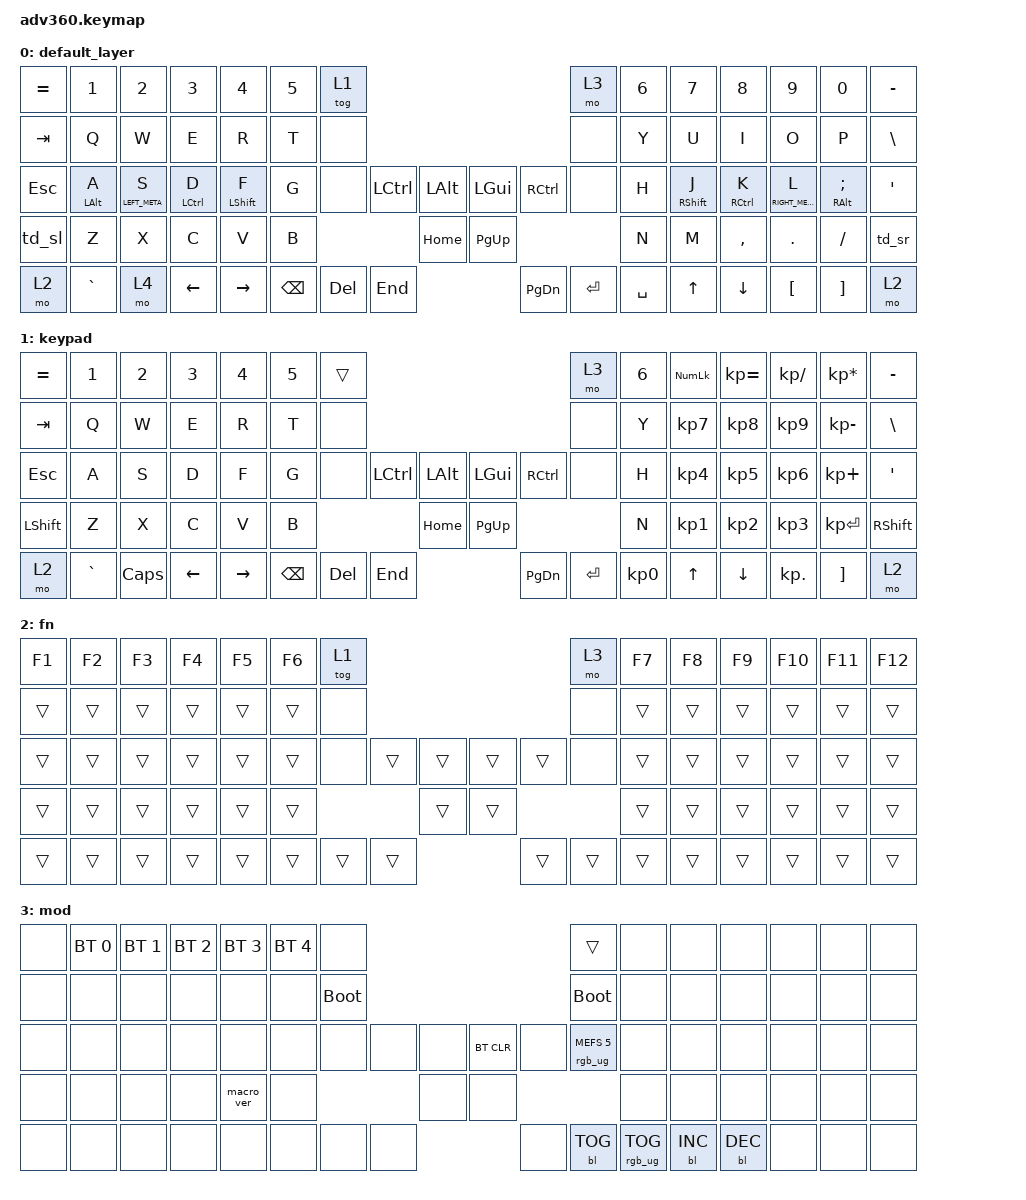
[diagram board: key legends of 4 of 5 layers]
#include <behaviors.dtsi>
#include <dt-bindings/zmk/keys.h>
#include <dt-bindings/zmk/bt.h>
#include <dt-bindings/zmk/rgb.h>
#include <dt-bindings/zmk/backlight.h>

/ {
    behaviors {
      #include "macros.dtsi"
      #include "version.dtsi"
      #ifndef VERSION_MACRO
      macro_ver: macro_ver {
        compatible = "zmk,behavior-macro";
        label = "macro_version";
        #binding-cells = <0>;
        bindings = <&kp RET>;
      };
      #endif

      hm: homerow_mods {
          compatible = "zmk,behavior-hold-tap";
          label = "HOMEROW_MODS";
          #binding-cells = <2>;
          tapping-term-ms = <200>;
          quick_tap_ms = <175>;
          require-prior-idle-ms = <125>;
          flavor = "tap-preferred";
          bindings = <&kp>, <&kp>;
      };

      td_sl: tap_dance_shift_left {
          compatible = "zmk,behavior-tap-dance";
          label = "TAP_DANCE_SHIFT_LEFT";
          tapping-term-ms = <300>;
          #binding-cells = <0>;
          bindings = <&kp LSHIFT>, <&caps_word>, <&kp CAPS>;
      };

      td_sr: tap_dance_shift_right {
          compatible = "zmk,behavior-tap-dance";
          label = "TAP_DANCE_SHIFT_RIGHT";
          tapping-term-ms = <300>;
          #binding-cells = <0>;
          bindings = <&kp RSHIFT>, <&caps_word>, <&kp CAPS>;
      };

    };

  keymap {
    compatible = "zmk,keymap";

    default_layer {
      bindings = <
        &kp EQUAL &kp N1    &kp N2   &kp N3   &kp N4     &kp N5 &tog 1                                                           &mo 3 &kp N6 &kp N7 &kp N8    &kp N9   &kp N0   &kp MINUS
        &kp TAB   &kp Q     &kp W    &kp E    &kp R      &kp T  &none                                                            &none &kp Y  &kp U  &kp I     &kp O    &kp P    &kp BSLH
        &kp ESC   &hm LEFT_ALT A     &hm LEFT_META S    &hm LEFT_CONTROL D    &hm LEFT_SHIFT F      &kp G  &none           &kp LCTRL &kp LALT &kp LGUI  &kp RCTRL           &none &kp H  &hm RIGHT_SHIFT J  &hm RIGHT_CONTROL K     &hm RIGHT_META L    &hm RIGHT_ALT SEMI &kp SQT
        &td_sl     &kp Z     &kp X    &kp C    &kp V      &kp B                            &kp HOME &kp PG_UP                           &kp N  &kp M  &kp COMMA &kp DOT  &kp FSLH &td_sr
        &mo 2     &kp GRAVE &mo 4 &kp LEFT &kp RIGHT                &kp BSPC &kp DEL   &kp END  &kp PG_DN &kp ENTER &kp SPACE              &kp UP &kp DOWN  &kp LBKT &kp RBKT &mo 2
      >;
    };
    keypad {
      bindings = <
        &kp EQUAL &kp N1    &kp N2   &kp N3   &kp N4     &kp N5 &trans                                                           &mo 3 &kp N6 &kp KP_NUM &kp KP_EQUAL &kp KP_DIVIDE &kp KP_MULTIPLY &kp MINUS
        &kp TAB   &kp Q     &kp W    &kp E    &kp R      &kp T  &none                                                            &none &kp Y  &kp KP_N7  &kp KP_N8    &kp KP_N9     &kp KP_MINUS    &kp BSLH
        &kp ESC   &kp A     &kp S    &kp D    &kp F      &kp G  &none           &kp LCTRL &kp LALT &kp LGUI  &kp RCTRL           &none &kp H  &kp KP_N4  &kp KP_N5    &kp KP_N6     &kp KP_PLUS     &kp SQT
        &kp LSHFT &kp Z     &kp X    &kp C    &kp V      &kp B                            &kp HOME &kp PG_UP                           &kp N  &kp KP_N1  &kp KP_N2    &kp KP_N3     &kp KP_ENTER    &kp RSHFT
        &mo 2     &kp GRAVE &kp CAPS &kp LEFT &kp RIGHT                &kp BSPC &kp DEL   &kp END  &kp PG_DN &kp ENTER &kp KP_N0              &kp UP     &kp DOWN     &kp KP_DOT    &kp RBKT        &mo 2
      >;
    };
    fn {
      bindings = <
        &kp F1 &kp F2 &kp F3 &kp F4 &kp F5 &kp F6 &tog 1                                           &mo 3 &kp F7 &kp F8 &kp F9 &kp F10 &kp F11 &kp F12
        &trans &trans &trans &trans &trans &trans  &none                                           &none &trans &trans &trans &trans  &trans  &trans
        &trans &trans &trans &trans &trans &trans  &none        &trans &trans &trans &trans        &none &trans &trans &trans &trans  &trans  &trans
        &trans &trans &trans &trans &trans &trans                      &trans &trans                     &trans &trans &trans &trans  &trans  &trans
        &trans &trans &trans &trans &trans               &trans &trans &trans &trans &trans &trans              &trans &trans &trans  &trans  &trans
      >;
    };
    mod {
      bindings = <
        &none &bt BT_SEL 0 &bt BT_SEL 1 &bt BT_SEL 2 &bt BT_SEL 3 &bt BT_SEL 4 &none                                                                     &trans                 &none        &none        &none        &none &none &none
        &none &none        &none        &none        &none        &none        &bootloader                                                               &bootloader            &none        &none        &none        &none &none &none
        &none &none        &none        &none        &none        &none        &none                   &none &none &bt BT_CLR &none                      &rgb_ug RGB_MEFS_CMD 5 &none        &none        &none        &none &none &none
        &none &none        &none        &none        &macro_ver   &none                                      &none &none                                                        &none        &none        &none        &none &none &none
        &none &none        &none        &none        &none                                       &none &none &none &none      &bl BL_TOG &rgb_ug RGB_TOG                                     &bl BL_INC   &bl BL_DEC   &none &none &none
      >;
    };
    layer_code {
            bindings = <
 &trans  &trans  &trans  &trans  &trans  &trans            &trans                                                  &trans  &trans                &trans          &trans           &trans                 &trans  &trans
 &trans  &trans  &trans  &trans  &trans  &trans            &trans                                                  &trans  &trans      &kp LEFT_BRACKET       &kp EQUAL    &kp AMPERSAND      &kp RIGHT_BRACKET  &trans
 &trans  &trans  &trans  &trans  &trans  &trans            &trans  &trans  &trans  &trans  &trans  &trans  &trans  &kp LEFT_PARENTHESIS  &kp LEFT_BRACE  &kp RIGHT_BRACE  &kp RIGHT_PARENTHESIS  &trans
 &trans  &trans  &trans  &trans  &trans  &trans            &trans  &trans  &trans  &trans  &trans  &trans  &trans  &trans  &trans                &trans          &trans           &trans                 &trans  &trans
 &trans  &trans  &trans  &trans  &trans                    &trans  &trans  &trans                  &trans  &trans  &trans                        &trans          &trans           &trans                 &trans  &trans
            >;
    };
  };
};

